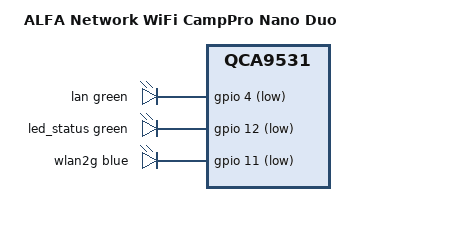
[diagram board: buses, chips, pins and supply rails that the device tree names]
// SPDX-License-Identifier: GPL-2.0-or-later OR MIT

#include <dt-bindings/leds/common.h>

#include "qca9531_alfa-network_r36a.dtsi"

/ {
	model = "ALFA Network WiFi CampPro Nano Duo";
	compatible = "alfa-network,wifi-camppro-nano-duo", "qca,qca9531";

	aliases {
		led-boot = &led_status;
		led-failsafe = &led_status;
		led-running = &led_status;
		led-upgrade = &led_status;
	};

	leds {
		compatible = "gpio-leds";

		pinctrl-names = "default";
		pinctrl-0 = <&enable_gpio4>;

		lan {
			function = LED_FUNCTION_LAN;
			color = <LED_COLOR_ID_GREEN>;
			gpios = <&gpio 4 GPIO_ACTIVE_LOW>;
		};

		led_status: status {
			function = LED_FUNCTION_STATUS;
			color = <LED_COLOR_ID_GREEN>;
			gpios = <&gpio 12 GPIO_ACTIVE_LOW>;
		};

		wlan2g {
			function = LED_FUNCTION_WLAN_2GHZ;
			color = <LED_COLOR_ID_BLUE>;
			gpios = <&gpio 11 GPIO_ACTIVE_LOW>;
			linux,default-trigger = "phy1tpt";
		};
	};
};

&eth0 {
	nvmem-cells = <&macaddr_art_1002 (-1)>;
	nvmem-cell-names = "mac-address";
};

&eth1 {
	compatible = "syscon", "simple-mfd";
};

&gpio_export {
	usb-power {
		gpio-export,name = "usb-power";
		gpio-export,output = <0>;
		gpios = <&gpio 3 GPIO_ACTIVE_LOW>;
	};
};
